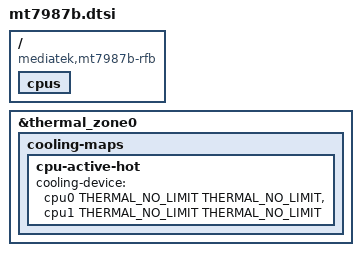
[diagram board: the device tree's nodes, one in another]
// SPDX-License-Identifier: (GPL-2.0 OR MIT)
/*
 * Copyright (C) 2024 MediaTek Inc.
 * Author: Sam.Shih <sam.shih@mediatek.com>
 */

#include "mt7987a.dtsi"

/ {
	compatible = "mediatek,mt7987b-rfb";

	cpus {
		/delete-node/ cpu@2;
		/delete-node/ cpu@3;
	};
};

&thermal_zone0 {
	cooling-maps {
		cpu-active-hot {
			cooling-device = <&cpu0 THERMAL_NO_LIMIT THERMAL_NO_LIMIT>,
					 <&cpu1 THERMAL_NO_LIMIT THERMAL_NO_LIMIT>;
		};
	};
};
